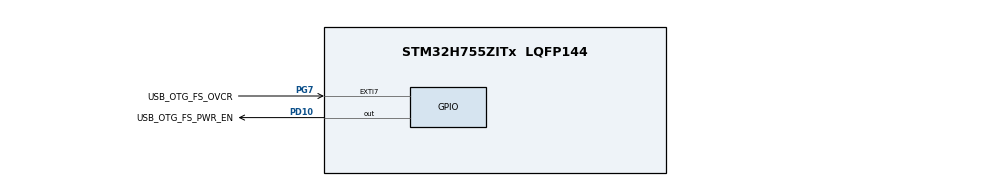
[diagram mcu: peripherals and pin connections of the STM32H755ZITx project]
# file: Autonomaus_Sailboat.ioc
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CortexM4.IPs=FATFS_M4\:I,FREERTOS_M4\:I,IWDG2\:I,RCC,WWDG2\:I,DMA,BDMA,MDMA,NVIC2\:I,ETH,USART3,DEBUG,PDM2PCM_M4\:I,PWR,RESMGR_UTILITY,SYS_M4\:I,USB_DEVICE_M4\:I,USB_HOST_M4\:I,CORTEX_M4\:I,GPIO,OPENAMP_M4\:I,VREFBUF,NUCLEO-H755ZI-Q
CortexM7.IPs=FATFS_M7\:I,FREERTOS_M7\:I,IWDG1\:I,RCC\:I,WWDG1\:I,DMA\:I,BDMA\:I,MDMA\:I,NVIC1\:I,ETH\:I,USART3\:I,USB_OTG_FS\:I,USB_OTG_FS1\:I,SYS\:I,CORTEX_M7\:I,DEBUG\:I,PDM2PCM_M7\:I,PWR\:I,RESMGR_UTILITY\:I,USB_DEVICE_M7\:I,USB_HOST_M7\:I,GPIO\:I,OPENAMP_M7\:I,VREFBUF\:I,NUCLEO-H755ZI-Q\:I
FREERTOS_M7.Tasks01=defaultTask,24,512,StartDefaultTask,Default,NULL,Dynamic,NULL,NULL
Mcu.Family=STM32H7
Mcu.Name=STM32H755ZITx
Mcu.Package=LQFP144
NUCLEO-H755ZI-Q.BUTTON=1
NUCLEO-H755ZI-Q.Bsp_Common_DEMO=true
NUCLEO-H755ZI-Q.LD1=true
NUCLEO-H755ZI-Q.LD2=true
NUCLEO-H755ZI-Q.LD3=true
NUCLEO-H755ZI-Q.VCP=true
NVIC1.EXTI15_10_IRQn=true\:5\:0\:false\:false\:true\:true\:false\:true\:true
NVIC1.PriorityGroup=NVIC_PRIORITYGROUP_4
NVIC2.PriorityGroup=NVIC_PRIORITYGROUP_4
PA1.PinAttribute=CortexM7
PA1.Signal=ETH_REF_CLK
PA11.PinAttribute=CortexM7
PA11.Signal=USB_OTG_FS_DM
PA12.PinAttribute=CortexM7
PA12.Signal=USB_OTG_FS_DP
PA2.PinAttribute=CortexM7
PA2.Signal=ETH_MDIO
PA7.PinAttribute=CortexM7
PA7.Signal=ETH_CRS_DV
PA8.PinAttribute=CortexM7
PA8.Signal=USB_OTG_FS_SOF
PA9.PinAttribute=CortexM7
PA9.Signal=USB_OTG_FS_VBUS
PB13.PinAttribute=CortexM7
PB13.Signal=ETH_TXD1
PC1.PinAttribute=CortexM7
PC1.Signal=ETH_MDC
PC14-OSC32_IN\ (OSC32_IN).PinAttribute=Free
PC14-OSC32_IN\ (OSC32_IN).Signal=RCC_OSC32_IN
PC15-OSC32_OUT\ (OSC32_OUT).PinAttribute=Free
PC15-OSC32_OUT\ (OSC32_OUT).Signal=RCC_OSC32_OUT
PC4.PinAttribute=CortexM7
PC4.Signal=ETH_RXD0
PC5.PinAttribute=CortexM7
PC5.Signal=ETH_RXD1
PD10.GPIO_Label=USB_OTG_FS_PWR_EN
PD10.PinAttribute=Free
PD10.Signal=GPIO_Output
PD8.Signal=USART3_TX
PD9.Signal=USART3_RX
PG11.PinAttribute=CortexM7
PG11.Signal=ETH_TX_EN
PG13.PinAttribute=CortexM7
PG13.Signal=ETH_TXD0
PG7.GPIO_Label=USB_OTG_FS_OVCR
PG7.PinAttribute=Free
PG7.Signal=GPXTI7
PH0-OSC_IN\ (PH0).PinAttribute=Free
PH0-OSC_IN\ (PH0).Signal=RCC_OSC_IN
PH1-OSC_OUT\ (PH1).PinAttribute=Free
PH1-OSC_OUT\ (PH1).Signal=RCC_OSC_OUT
ProjectManager.HeapSize=M4-0x200,M7-0x200
ProjectManager.StackSize=M4-0x400,M7-0x400
ProjectManager.TargetToolchain=CMake
RCC.ADCFreq_Value=129000000
RCC.APB1Freq_Value=64000000
RCC.APB2Freq_Value=64000000
RCC.APB3Freq_Value=64000000
RCC.APB4Freq_Value=64000000
RCC.CortexFreq_Value=64000000
RCC.DIVM1=5
RCC.DIVN1=48
RCC.DIVQ1=5
RCC.HCLKFreq_Value=64000000
RCC.PLL2FRACN=0
RCC.PLL3FRACN=0
RCC.PLLFRACN=0
RCC.SYSCLKFreq_VALUE=64000000
RCC.SupplySource=PWR_DIRECT_SMPS_SUPPLY
RCC.USBFreq_Value=122880000
VP_FREERTOS_M7_VS_CMSIS_V2.Mode=CMSIS_V2
VP_NUCLEO-H755ZI-Q_VS_BSP_COMMON.Mode=COMMON
VP_SYS_M4_VS_Systick.Mode=SysTick
board=NUCLEO-H755ZI-Q

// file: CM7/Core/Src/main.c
#include "main.h"
#include "cmsis_os2.h"
#include "portmacro.h"
#include "stm32h7xx_hal_conf.h"
#include "stm32h7xx_hal_gpio.h"
#include "stm32h7xx_hal_rcc.h"
#include <stdint.h>

#include "button.h"

#include "servoSail.h"
#include "servoRudder.h"

#include "sensorWind.h"
#include "sensorMagnetometer.h"
#include "sensorEncoder.h"
#include "sensorGPS.h"

//...

//...

/* DUAL_CORE_BOOT_SYNC_SEQUENCE: Define for dual core boot synchronization    */
/*                             demonstration code based on hardware semaphore */
/* This define is present in both CM7/CM4 projects                            */
/* To comment when developping/debugging on a single core                     */
#define DUAL_CORE_BOOT_SYNC_SEQUENCE

#if defined(DUAL_CORE_BOOT_SYNC_SEQUENCE)
#ifndef HSEM_ID_0
#define HSEM_ID_0 (0U) /* HW semaphore 0*/
#endif
#endif /* DUAL_CORE_BOOT_SYNC_SEQUENCE */

//...

COM_InitTypeDef BspCOMInit;

TaskHandle_t task_live;

void SystemClock_Config(void);
void hardware_init(void);
void rtos_init(void);

void live_hardwareInit();
void live_handler(void *argument);

int main(void)
{
  // Dual Boot Sequence --------------------------------------------------------
  // This sequence is based on the hardware semaphore IP, and ensures that both
  // cores are correctly booted and can run independently.
  //
  // It works as follows:
  // 1) When the CM7 boots, it will wait until the CM4 boots and enters in stop mode (RCC_FLAG_D2CKRDY flag is reset)
  // 2) When the CM4 is in stop mode, the CM7 will release the CM4 by means of a hardware semaphore notification (HSEM_ID_0)
  // 3) When the CM4 receives the notification, it will exit stop mode and the RCC_FLAG_D2CKRDY flag will be set, which the CM7 is waiting for in step 1)
  // 4) When the CM7 detects that the CM4 is out of stop mode, it will continue
  // 5) Perform the hardware initialization
  // 6) Start the RTOS scheduler.

  #if defined(DUAL_CORE_BOOT_SYNC_SEQUENCE)
    uint16_t timeout = 0xFFFF;
    while((__HAL_RCC_GET_FLAG(RCC_FLAG_D2CKRDY) != RESET) && (timeout-- > 0));
    if ( timeout < 0 ) { Error_Handler(); }
  #endif

  hardware_init();
  rtos_init();
  vTaskStartScheduler();
}

void SystemClock_Config(void)
{
  RCC_OscInitTypeDef RCC_OscInitStruct = {0};
  RCC_ClkInitTypeDef RCC_ClkInitStruct = {0};

  /** Supply configuration update enable
  */
  HAL_PWREx_ConfigSupply(PWR_DIRECT_SMPS_SUPPLY);

  /** Configure the main internal regulator output voltage
  */
  __HAL_PWR_VOLTAGESCALING_CONFIG(PWR_REGULATOR_VOLTAGE_SCALE3);

  while(!__HAL_PWR_GET_FLAG(PWR_FLAG_VOSRDY)) {}

  /** Initializes the RCC Oscillators according to the specified parameters
  * in the RCC_OscInitTypeDef structure.
  */
  RCC_OscInitStruct.OscillatorType = RCC_OSCILLATORTYPE_HSI;
  RCC_OscInitStruct.HSIState = RCC_HSI_DIV1;
  RCC_OscInitStruct.HSICalibrationValue = RCC_HSICALIBRATION_DEFAULT;
  RCC_OscInitStruct.PLL.PLLState = RCC_PLL_NONE;
  if (HAL_RCC_OscConfig(&RCC_OscInitStruct) != HAL_OK)
  {
    Error_Handler();
  }

  /** Initializes the CPU, AHB and APB buses clocks
  */
  RCC_ClkInitStruct.ClockType = RCC_CLOCKTYPE_HCLK|RCC_CLOCKTYPE_SYSCLK
                              |RCC_CLOCKTYPE_PCLK1|RCC_CLOCKTYPE_PCLK2
                              |RCC_CLOCKTYPE_D3PCLK1|RCC_CLOCKTYPE_D1PCLK1;
  RCC_ClkInitStruct.SYSCLKSource = RCC_SYSCLKSOURCE_HSI;
  RCC_ClkInitStruct.SYSCLKDivider = RCC_SYSCLK_DIV1;
  RCC_ClkInitStruct.AHBCLKDivider = RCC_HCLK_DIV1;
  RCC_ClkInitStruct.APB3CLKDivider = RCC_APB3_DIV1;
  RCC_ClkInitStruct.APB1CLKDivider = RCC_APB1_DIV1;
  RCC_ClkInitStruct.APB2CLKDivider = RCC_APB2_DIV1;
  RCC_ClkInitStruct.APB4CLKDivider = RCC_APB4_DIV1;

  if (HAL_RCC_ClockConfig(&RCC_ClkInitStruct, FLASH_LATENCY_1) != HAL_OK)
  {
    Error_Handler();
  }
}

void Error_Handler(void)
{
  __disable_irq();
  while (1)
  {
  }
}

/**
  * @brief  Initialize the hardware components.
  * 1) HAL_Init() is called to initialize the Hardware Abstraction Layer, which will set up the system clock, configure the SysTick timer, and perform any necessary low-level hardware initialization.
  * 2) User defined hardware setup.
  * 3) SystemClock_Config() is called to configure the system clock according to the application's requirements. This function typically sets up the main system clock source, configures the PLL (Phase-Locked Loop) if used, and sets the appropriate clock dividers for the AHB and APB buses.
  * 4) Release the CM4 after hardware initialization is done.
  * 5) Start the COM1 serial port for debugging purposes.
  *
  * @retval None
  */
void hardware_init(void)
{
  HAL_Init();
  __HAL_RCC_GPIOA_CLK_ENABLE();
  __HAL_RCC_GPIOB_CLK_ENABLE();
  __HAL_RCC_GPIOC_CLK_ENABLE();
  __HAL_RCC_GPIOE_CLK_ENABLE();
  __HAL_RCC_GPIOF_CLK_ENABLE();

  __HAL_RCC_TIM1_CLK_ENABLE();
  __HAL_RCC_UART4_CLK_ENABLE();
  __HAL_RCC_I2C2_CLK_ENABLE();
  __HAL_RCC_I2C1_CLK_ENABLE();
  __HAL_RCC_UART7_CLK_ENABLE();

  SystemClock_Config();

  #if defined(DUAL_CORE_BOOT_SYNC_SEQUENCE)
    __HAL_RCC_HSEM_CLK_ENABLE();
    HAL_HSEM_FastTake(HSEM_ID_0);
    HAL_HSEM_Release(HSEM_ID_0,0);
    uint16_t timeout = 0xFFFF;
    while((__HAL_RCC_GET_FLAG(RCC_FLAG_D2CKRDY) == RESET) && (timeout-- > 0));
    if ( timeout < 0 ) { Error_Handler(); }
  #endif

  /* Initialize COM1 port (115200, 8 bits (7-bit data + 1 stop bit), no parity */
  BspCOMInit.BaudRate   = 115200;
  BspCOMInit.WordLength = COM_WORDLENGTH_8B;
  BspCOMInit.StopBits   = COM_STOPBITS_1;
  BspCOMInit.Parity     = COM_PARITY_NONE;
  BspCOMInit.HwFlowCtl  = COM_HWCONTROL_NONE;
  if (BSP_COM_Init(COM1, &BspCOMInit) != BSP_ERROR_NONE)
  {
    Error_Handler();
  }

  // Should already be in your STM32H7 HAL init but verify:
  SCB->CPACR |= ((3UL << 10*2) | (3UL << 11*2));  // enable FPU

  /* USER CODE BEGIN SysInit */
  live_hardwareInit();
  button_hardwareInit();

  servoSail_hardwareInit();
  servoRudder_hardwareInit();

  sensorWind_hardwareInit();
  sensorMagnetometer_hardwareInit();
  sensorEncoder_hardwareInit();
  sensorGPS_hardwareInit();
  /* USER CODE END SysInit */

}

/**
  * @brief  Initialize the Real-Time Operating System and all of its components.
  * @retval None
  */
void rtos_init()
{
  if ((semphr_button = xSemaphoreCreateBinary()) == NULL) { Error_Handler(); }

  if (xTaskCreate(live_handler,               "liveTask",               64,  NULL, osPriorityNormal,      &task_live)               != pdPASS) { Error_Handler(); }
  if (xTaskCreate(button_handler,             "buttonTask",             64,  NULL, osPriorityNormal,      &task_button)             != pdPASS) { Error_Handler(); }
  if (xTaskCreate(servoSail_handler,          "servoSailTask",          128, NULL, osPriorityNormal,      &task_servoSail)          != pdPASS) { Error_Handler(); }
  if (xTaskCreate(servoRudder_handler,        "servoRudderTask",        128, NULL, osPriorityNormal,      &task_servoRudder)        != pdPASS) { Error_Handler(); }
  if (xTaskCreate(sensorWind_handler,         "sensorWindTask",         512, NULL, osPriorityAboveNormal, &task_sensorWind)         != pdPASS) { Error_Handler(); }
  if (xTaskCreate(sensorMagnetometer_handler, "sensorMagnetometerTask", 128, NULL, osPriorityAboveNormal, &task_sensorMagnetometer) != pdPASS) { Error_Handler(); }
  if (xTaskCreate(sensorEncoder_handler,      "sensorEncoderTask",      256, NULL, osPriorityAboveNormal, &task_sensorEncoder)      != pdPASS) { Error_Handler(); }
  if (xTaskCreate(sensorGPS_handler,          "sensorGPSTask",          512, NULL, osPriorityAboveNormal, &task_sensorGPS)          != pdPASS) { Error_Handler(); }
}

///////////////////////////////////////////////////////////////////////////////////////////////////
// Live Functions
///////////////////////////////////////////////////////////////////////////////////////////////////

void live_hardwareInit()
{
  GPIO_InitTypeDef GPIO_InitStruct = {0};

  GPIO_InitStruct.Pin = GPIO_PIN_0;
  GPIO_InitStruct.Mode = GPIO_MODE_OUTPUT_PP;
  GPIO_InitStruct.Pull = GPIO_NOPULL;
  GPIO_InitStruct.Speed = GPIO_SPEED_FREQ_LOW;
  HAL_GPIO_Init(GPIOB, &GPIO_InitStruct);
}

void live_handler(void *argument)
{
  for(;;)
  {
    HAL_GPIO_TogglePin(GPIOB, GPIO_PIN_0);
    vTaskDelay(1000 * portTICK_PERIOD_MS);
  }
}
